# nrf54lm20a_enga_application register map
Vendor: Nordic Semiconductor; Series: nrf54l; File version: 1
CPU: CM33 r0p4, little endian, MPU, FPU, 3 interrupt priority bits, 270 interrupts, 4 SAU regions
Registers are 32-bit, read-write, reset 0x0 unless marked. A register's access mark holds for its fields unless they carry their own. Offsets are from the block's base; [hi:lo] are bit positions; lines under a group give offsets from that group; 'fields as' and 'values as' point back to an identical list.

## GLOBAL_NFCT_NS — NFC-A compatible radio NFC-A compatible radio 0
Base 0x400D6000
Same registers: GLOBAL_NFCT_S 0x500D6000
0x00 TASKS_ACTIVATE wo — Activate NFCT peripheral for incoming and outgoing frames, change state to activated
  [0] TASKS_ACTIVATE
    1=Trigger task
0x04 TASKS_DISABLE wo — Disable NFCT peripheral
  [0] TASKS_DISABLE
    1=Trigger task
0x08 TASKS_SENSE wo — Enable NFC sense field mode, change state to sense mode
  [0] TASKS_SENSE
    1=Trigger task
0x0C TASKS_STARTTX wo — Start transmission of an outgoing frame, change state to transmit
  [0] TASKS_STARTTX
    1=Trigger task
0x10 TASKS_STOPTX wo — Stops an issued transmission of a frame
  [0] TASKS_STOPTX
    1=Trigger task
0x1C TASKS_ENABLERXDATA wo — Initializes the EasyDMA for receive.
  [0] TASKS_ENABLERXDATA
    1=Trigger task
0x24 TASKS_GOIDLE wo — Force state machine to IDLE state
  [0] TASKS_GOIDLE
    1=Trigger task
0x28 TASKS_GOSLEEP wo — Force state machine to SLEEP_A state
  [0] TASKS_GOSLEEP
    1=Trigger task
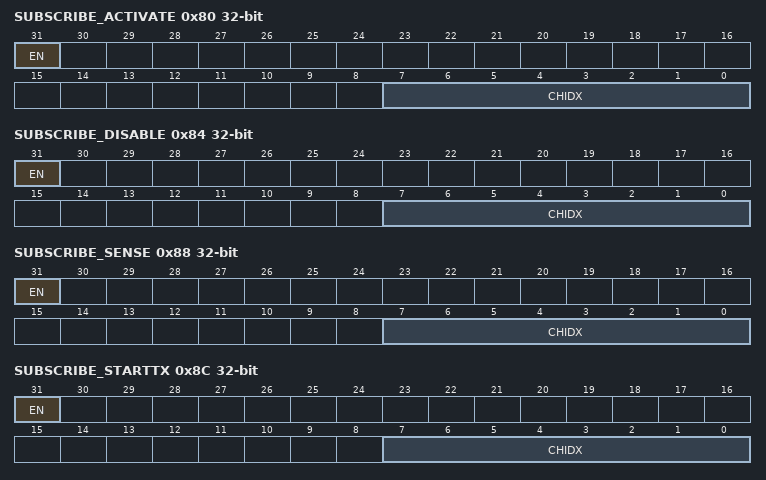
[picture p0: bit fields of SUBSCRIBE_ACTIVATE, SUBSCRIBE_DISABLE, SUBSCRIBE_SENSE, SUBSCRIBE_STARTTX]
0x80 SUBSCRIBE_ACTIVATE — Subscribe configuration for task ACTIVATE
  [31] EN
    0=Disabled (Disable subscription); 1=Enabled (Enable subscription)
  [7:0] CHIDX — DPPI channel that task ACTIVATE will subscribe to
0x84 SUBSCRIBE_DISABLE — Subscribe configuration for task DISABLE
  [31] EN
    values as SUBSCRIBE_ACTIVATE.EN
  [7:0] CHIDX — DPPI channel that task DISABLE will subscribe to
0x88 SUBSCRIBE_SENSE — Subscribe configuration for task SENSE
  [31] EN
    values as SUBSCRIBE_ACTIVATE.EN
  [7:0] CHIDX — DPPI channel that task SENSE will subscribe to
0x8C SUBSCRIBE_STARTTX — Subscribe configuration for task STARTTX
  [31] EN
    values as SUBSCRIBE_ACTIVATE.EN
  [7:0] CHIDX — DPPI channel that task STARTTX will subscribe to
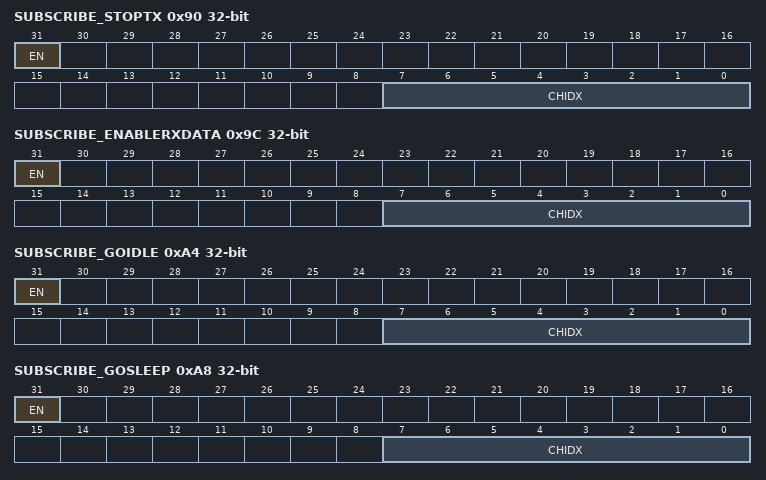
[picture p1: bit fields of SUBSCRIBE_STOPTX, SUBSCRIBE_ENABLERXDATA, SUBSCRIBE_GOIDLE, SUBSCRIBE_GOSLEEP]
0x90 SUBSCRIBE_STOPTX — Subscribe configuration for task STOPTX
  [31] EN
    values as SUBSCRIBE_ACTIVATE.EN
  [7:0] CHIDX — DPPI channel that task STOPTX will subscribe to
0x9C SUBSCRIBE_ENABLERXDATA — Subscribe configuration for task ENABLERXDATA
  [31] EN
    values as SUBSCRIBE_ACTIVATE.EN
  [7:0] CHIDX — DPPI channel that task ENABLERXDATA will subscribe to
0xA4 SUBSCRIBE_GOIDLE — Subscribe configuration for task GOIDLE
  [31] EN
    values as SUBSCRIBE_ACTIVATE.EN
  [7:0] CHIDX — DPPI channel that task GOIDLE will subscribe to
0xA8 SUBSCRIBE_GOSLEEP — Subscribe configuration for task GOSLEEP
  [31] EN
    values as SUBSCRIBE_ACTIVATE.EN
  [7:0] CHIDX — DPPI channel that task GOSLEEP will subscribe to
0x100 EVENTS_READY — The NFCT peripheral is ready to receive and send frames
  [0] EVENTS_READY
    0=NotGenerated (Event not generated); 1=Generated (Event generated)
0x104 EVENTS_FIELDDETECTED — Remote NFC field detected
  [0] EVENTS_FIELDDETECTED
    values as EVENTS_READY.EVENTS_READY
0x108 EVENTS_FIELDLOST — Remote NFC field lost
  [0] EVENTS_FIELDLOST
    values as EVENTS_READY.EVENTS_READY
0x10C EVENTS_TXFRAMESTART — Marks the start of the first symbol of a transmitted frame
  [0] EVENTS_TXFRAMESTART
    values as EVENTS_READY.EVENTS_READY
0x110 EVENTS_TXFRAMEEND — Marks the end of the last transmitted on-air symbol of a frame
  [0] EVENTS_TXFRAMEEND
    values as EVENTS_READY.EVENTS_READY
0x114 EVENTS_RXFRAMESTART — Marks the end of the first symbol of a received frame
  [0] EVENTS_RXFRAMESTART
    values as EVENTS_READY.EVENTS_READY
0x118 EVENTS_RXFRAMEEND — Received data has been checked (CRC, parity) and transferred to RAM, and EasyDMA has ended accessing the RX buffer
  [0] EVENTS_RXFRAMEEND
    values as EVENTS_READY.EVENTS_READY
0x11C EVENTS_ERROR — NFC error reported. The ERRORSTATUS register contains details on the source of the error.
  [0] EVENTS_ERROR
    values as EVENTS_READY.EVENTS_READY
0x128 EVENTS_RXERROR — NFC RX frame error reported. The FRAMESTATUS.RX register contains details on the source of the error.
  [0] EVENTS_RXERROR
    values as EVENTS_READY.EVENTS_READY
0x12C EVENTS_ENDRX — RX buffer (as defined by PACKETPTR and MAXLEN) in Data RAM full.
  [0] EVENTS_ENDRX
    values as EVENTS_READY.EVENTS_READY
0x130 EVENTS_ENDTX — Transmission of data in RAM has ended, and EasyDMA has ended accessing the TX buffer
  [0] EVENTS_ENDTX
    values as EVENTS_READY.EVENTS_READY
0x138 EVENTS_AUTOCOLRESSTARTED — Auto collision resolution process has started
  [0] EVENTS_AUTOCOLRESSTARTED
    values as EVENTS_READY.EVENTS_READY
0x148 EVENTS_COLLISION — NFC auto collision resolution error reported.
  [0] EVENTS_COLLISION
    values as EVENTS_READY.EVENTS_READY
0x14C EVENTS_SELECTED — NFC auto collision resolution successfully completed
  [0] EVENTS_SELECTED
    values as EVENTS_READY.EVENTS_READY
0x150 EVENTS_STARTED — EasyDMA is ready to receive or send frames.
  [0] EVENTS_STARTED
    values as EVENTS_READY.EVENTS_READY
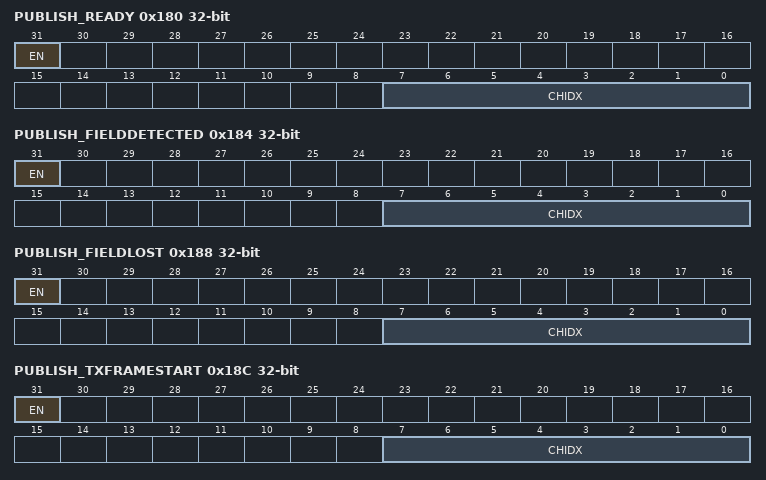
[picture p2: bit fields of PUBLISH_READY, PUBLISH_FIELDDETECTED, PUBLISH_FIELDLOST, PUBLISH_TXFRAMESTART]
0x180 PUBLISH_READY — Publish configuration for event READY
  [31] EN
    0=Disabled (Disable publishing); 1=Enabled (Enable publishing)
  [7:0] CHIDX — DPPI channel that event READY will publish to
0x184 PUBLISH_FIELDDETECTED — Publish configuration for event FIELDDETECTED
  [31] EN
    values as PUBLISH_READY.EN
  [7:0] CHIDX — DPPI channel that event FIELDDETECTED will publish to
0x188 PUBLISH_FIELDLOST — Publish configuration for event FIELDLOST
  [31] EN
    values as PUBLISH_READY.EN
  [7:0] CHIDX — DPPI channel that event FIELDLOST will publish to
0x18C PUBLISH_TXFRAMESTART — Publish configuration for event TXFRAMESTART
  [31] EN
    values as PUBLISH_READY.EN
  [7:0] CHIDX — DPPI channel that event TXFRAMESTART will publish to
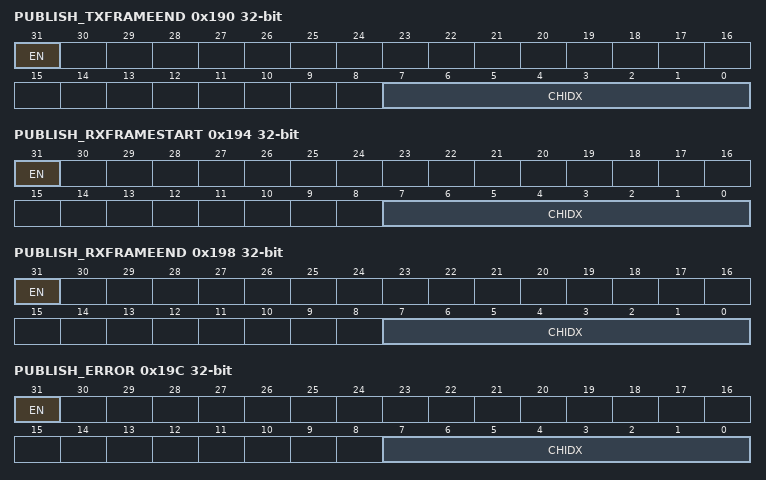
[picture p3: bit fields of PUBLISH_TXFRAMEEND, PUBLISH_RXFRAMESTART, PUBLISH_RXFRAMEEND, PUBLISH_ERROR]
0x190 PUBLISH_TXFRAMEEND — Publish configuration for event TXFRAMEEND
  [31] EN
    values as PUBLISH_READY.EN
  [7:0] CHIDX — DPPI channel that event TXFRAMEEND will publish to
0x194 PUBLISH_RXFRAMESTART — Publish configuration for event RXFRAMESTART
  [31] EN
    values as PUBLISH_READY.EN
  [7:0] CHIDX — DPPI channel that event RXFRAMESTART will publish to
0x198 PUBLISH_RXFRAMEEND — Publish configuration for event RXFRAMEEND
  [31] EN
    values as PUBLISH_READY.EN
  [7:0] CHIDX — DPPI channel that event RXFRAMEEND will publish to
0x19C PUBLISH_ERROR — Publish configuration for event ERROR
  [31] EN
    values as PUBLISH_READY.EN
  [7:0] CHIDX — DPPI channel that event ERROR will publish to
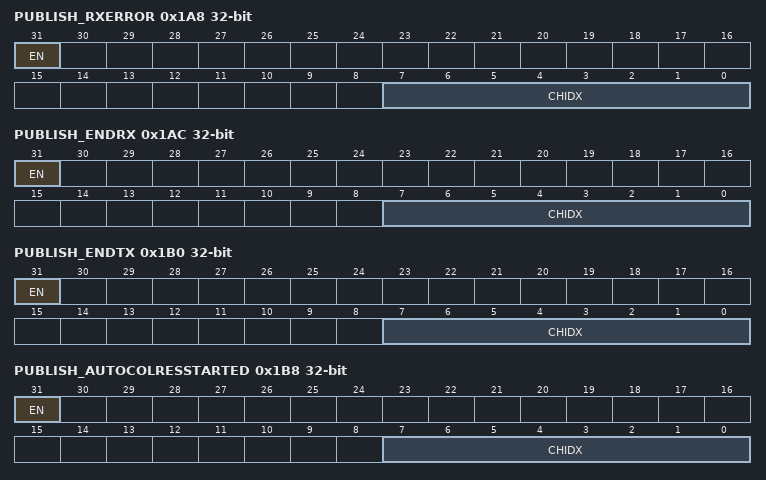
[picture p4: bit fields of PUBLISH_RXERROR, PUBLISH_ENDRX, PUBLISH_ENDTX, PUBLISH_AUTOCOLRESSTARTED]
0x1A8 PUBLISH_RXERROR — Publish configuration for event RXERROR
  [31] EN
    values as PUBLISH_READY.EN
  [7:0] CHIDX — DPPI channel that event RXERROR will publish to
0x1AC PUBLISH_ENDRX — Publish configuration for event ENDRX
  [31] EN
    values as PUBLISH_READY.EN
  [7:0] CHIDX — DPPI channel that event ENDRX will publish to
0x1B0 PUBLISH_ENDTX — Publish configuration for event ENDTX
  [31] EN
    values as PUBLISH_READY.EN
  [7:0] CHIDX — DPPI channel that event ENDTX will publish to
0x1B8 PUBLISH_AUTOCOLRESSTARTED — Publish configuration for event AUTOCOLRESSTARTED
  [31] EN
    values as PUBLISH_READY.EN
  [7:0] CHIDX — DPPI channel that event AUTOCOLRESSTARTED will publish to
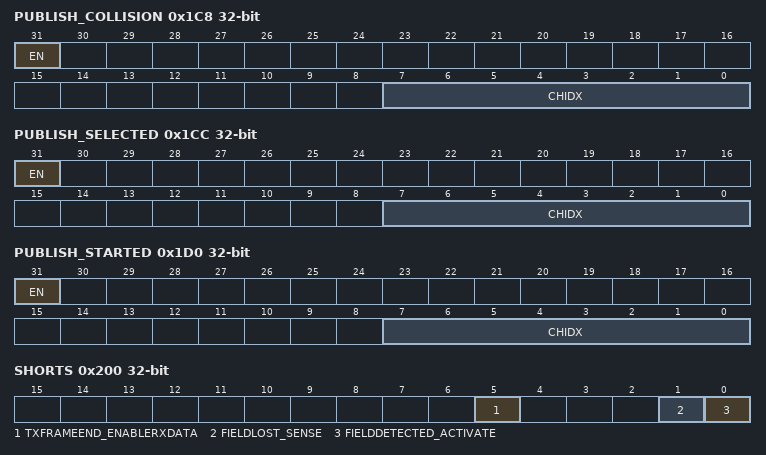
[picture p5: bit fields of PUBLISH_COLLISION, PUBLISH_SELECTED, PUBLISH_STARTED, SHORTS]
0x1C8 PUBLISH_COLLISION — Publish configuration for event COLLISION
  [31] EN
    values as PUBLISH_READY.EN
  [7:0] CHIDX — DPPI channel that event COLLISION will publish to
0x1CC PUBLISH_SELECTED — Publish configuration for event SELECTED
  [31] EN
    values as PUBLISH_READY.EN
  [7:0] CHIDX — DPPI channel that event SELECTED will publish to
0x1D0 PUBLISH_STARTED — Publish configuration for event STARTED
  [31] EN
    values as PUBLISH_READY.EN
  [7:0] CHIDX — DPPI channel that event STARTED will publish to
0x200 SHORTS — Shortcuts between local events and tasks
  [all] fields
    0=Disabled (Disable shortcut); 1=Enabled (Enable shortcut)
  [5] TXFRAMEEND_ENABLERXDATA — Shortcut between event TXFRAMEEND and task ENABLERXDATA
  [1] FIELDLOST_SENSE — Shortcut between event FIELDLOST and task SENSE
  [0] FIELDDETECTED_ACTIVATE — Shortcut between event FIELDDETECTED and task ACTIVATE
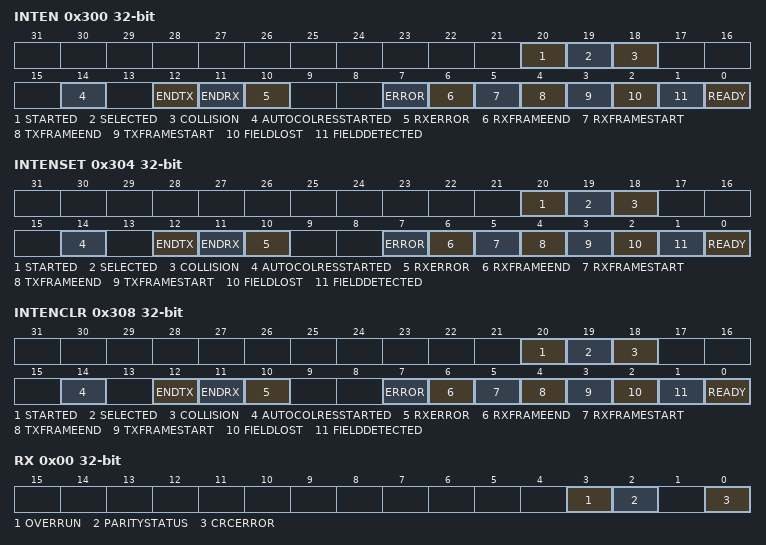
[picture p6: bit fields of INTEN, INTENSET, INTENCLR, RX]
0x300 INTEN — Enable or disable interrupt
  [all] fields
    0=Disabled; 1=Enabled
  [20] STARTED — Enable or disable interrupt for event STARTED
  [19] SELECTED — Enable or disable interrupt for event SELECTED
  [18] COLLISION — Enable or disable interrupt for event COLLISION
  [14] AUTOCOLRESSTARTED — Enable or disable interrupt for event AUTOCOLRESSTARTED
  [12] ENDTX — Enable or disable interrupt for event ENDTX
  [11] ENDRX — Enable or disable interrupt for event ENDRX
  [10] RXERROR — Enable or disable interrupt for event RXERROR
  [7] ERROR — Enable or disable interrupt for event ERROR
  [6] RXFRAMEEND — Enable or disable interrupt for event RXFRAMEEND
  [5] RXFRAMESTART — Enable or disable interrupt for event RXFRAMESTART
  [4] TXFRAMEEND — Enable or disable interrupt for event TXFRAMEEND
  [3] TXFRAMESTART — Enable or disable interrupt for event TXFRAMESTART
  [2] FIELDLOST — Enable or disable interrupt for event FIELDLOST
  [1] FIELDDETECTED — Enable or disable interrupt for event FIELDDETECTED
  [0] READY — Enable or disable interrupt for event READY
0x304 INTENSET — Enable interrupt
  [all] fields
    on read: 0=Disabled (Read: Disabled); 1=Enabled (Read: Enabled) | on write: 1=Set (Enable)
  [20] STARTED write-1-sets — Write '1' to enable interrupt for event STARTED
  [19] SELECTED write-1-sets — Write '1' to enable interrupt for event SELECTED
  [18] COLLISION write-1-sets — Write '1' to enable interrupt for event COLLISION
  [14] AUTOCOLRESSTARTED write-1-sets — Write '1' to enable interrupt for event AUTOCOLRESSTARTED
  [12] ENDTX write-1-sets — Write '1' to enable interrupt for event ENDTX
  [11] ENDRX write-1-sets — Write '1' to enable interrupt for event ENDRX
  [10] RXERROR write-1-sets — Write '1' to enable interrupt for event RXERROR
  [7] ERROR write-1-sets — Write '1' to enable interrupt for event ERROR
  [6] RXFRAMEEND write-1-sets — Write '1' to enable interrupt for event RXFRAMEEND
  [5] RXFRAMESTART write-1-sets — Write '1' to enable interrupt for event RXFRAMESTART
  [4] TXFRAMEEND write-1-sets — Write '1' to enable interrupt for event TXFRAMEEND
  [3] TXFRAMESTART write-1-sets — Write '1' to enable interrupt for event TXFRAMESTART
  [2] FIELDLOST write-1-sets — Write '1' to enable interrupt for event FIELDLOST
  [1] FIELDDETECTED write-1-sets — Write '1' to enable interrupt for event FIELDDETECTED
  [0] READY write-1-sets — Write '1' to enable interrupt for event READY
0x308 INTENCLR — Disable interrupt
  [all] fields
    on read: 0=Disabled (Read: Disabled); 1=Enabled (Read: Enabled) | on write: 1=Clear (Disable)
  [20] STARTED write-1-clears — Write '1' to disable interrupt for event STARTED
  [19] SELECTED write-1-clears — Write '1' to disable interrupt for event SELECTED
  [18] COLLISION write-1-clears — Write '1' to disable interrupt for event COLLISION
  [14] AUTOCOLRESSTARTED write-1-clears — Write '1' to disable interrupt for event AUTOCOLRESSTARTED
  [12] ENDTX write-1-clears — Write '1' to disable interrupt for event ENDTX
  [11] ENDRX write-1-clears — Write '1' to disable interrupt for event ENDRX
  [10] RXERROR write-1-clears — Write '1' to disable interrupt for event RXERROR
  [7] ERROR write-1-clears — Write '1' to disable interrupt for event ERROR
  [6] RXFRAMEEND write-1-clears — Write '1' to disable interrupt for event RXFRAMEEND
  [5] RXFRAMESTART write-1-clears — Write '1' to disable interrupt for event RXFRAMESTART
  [4] TXFRAMEEND write-1-clears — Write '1' to disable interrupt for event TXFRAMEEND
  [3] TXFRAMESTART write-1-clears — Write '1' to disable interrupt for event TXFRAMESTART
  [2] FIELDLOST write-1-clears — Write '1' to disable interrupt for event FIELDLOST
  [1] FIELDDETECTED write-1-clears — Write '1' to disable interrupt for event FIELDDETECTED
  [0] READY write-1-clears — Write '1' to disable interrupt for event READY
0x404 ERRORSTATUS write-1-clears — NFC Error Status register
  [0] FRAMEDELAYTIMEOUT — No STARTTX task triggered before expiration of the time set in FRAMEDELAYMAX
0x40C FRAMESTATUS group — Unspecified
  0x00 RX write-1-clears — Result of last incoming frame
    [3] OVERRUN — Overrun detected
      0=No overrun detected; 1=Overrun error
    [2] PARITYSTATUS — Parity status of received frame
      0=ParityOK (Frame received with parity OK); 1=ParityError (Frame received with parity error)
    [0] CRCERROR — No valid end of frame (EoF) detected
      0=CRCCorrect (Valid CRC detected); 1=CRCError (CRC received does not match local check)
0x410 NFCTAGSTATE ro — Current operating state of NFC tag
  [2:0] NFCTAGSTATE
    0=Disabled or sense; 2=RampUp; 3=Idle; 4=Receive; 5=FrameDelay; 6=Transmit
0x420 SLEEPSTATE ro — Sleep state during automatic collision resolution
  [0] SLEEPSTATE — Reflects the sleep state during automatic collision resolution. Set to IDLE by a GOIDLE task. Set to SLEEP_A when a valid SLEEP_REQ frame is received or by a GOSLEEP task.
    0=Idle (State is IDLE.); 1=SleepA (State is SLEEP_A.)
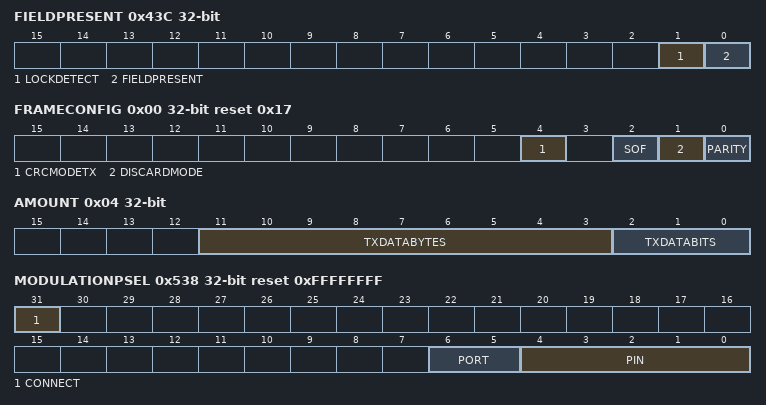
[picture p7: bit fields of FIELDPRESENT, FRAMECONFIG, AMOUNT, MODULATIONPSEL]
0x43C FIELDPRESENT ro — Indicates the presence or not of a valid field
  [1] LOCKDETECT — Indicates if the low level has locked to the field
    0=Not locked to field; 1=Locked to field
  [0] FIELDPRESENT — Indicates if a valid field is present. Available only in the activated state.
    0=NoField (No valid field detected); 1=FieldPresent (Valid field detected)
0x504 FRAMEDELAYMIN reset 0x480 — Minimum frame delay
  [15:0] FRAMEDELAYMIN — Minimum frame delay in number of 13.56 MHz clock cycles
0x508 FRAMEDELAYMAX reset 0x1000 — Maximum frame delay
  [19:0] FRAMEDELAYMAX — Maximum frame delay in number of 13.56 MHz clock cycles
0x50C FRAMEDELAYMODE reset 0x1 — Configuration register for the Frame Delay Timer
  [1:0] FRAMEDELAYMODE
    0=FreeRun (Transmission is independent of frame timer and will start when the STARTTX task is triggered. No timeout.); 1=Window (Frame is transmitted between FRAMEDELAYMIN and FRAMEDELAYMAX); 2=ExactVal (Frame is transmitted exactly at FRAMEDELAYMAX); 3=WindowGrid (Frame is transmitted on a bit grid between FRAMEDELAYMIN and FRAMEDELAYMAX)
0x510 PACKETPTR — Packet pointer for TXD and RXD data storage in Data RAM
  [31:0] PTR — Packet pointer for TXD and RXD data storage in Data RAM. This address is a byte-aligned RAM address.
0x514 MAXLEN — Size of the RAM buffer allocated to TXD and RXD data storage each
  [8:0] MAXLEN
0x518 TXD group — Unspecified
  0x00 FRAMECONFIG reset 0x17 — Configuration of outgoing frames
    [4] CRCMODETX — CRC mode for outgoing frames
      0=NoCRCTX (CRC is not added to the frame); 1=CRC16TX (16 bit CRC added to the frame based on all the data read from RAM that is used in the frame)
    [2] SOF — Adding SoF or not in TX frames
      0=NoSoF (SoF symbol not added); 1=SoF (SoF symbol added)
    [1] DISCARDMODE — Discarding unused bits at start or end of a frame
      0=DiscardEnd (Unused bits are discarded at end of frame (EoF)); 1=DiscardStart (Unused bits are discarded at start of frame (SoF))
    [0] PARITY — Indicates if parity is added to the frame
      0=NoParity (Parity is not added to TX frames); 1=Parity is added to TX frames
  0x04 AMOUNT — Size of outgoing frame
    [11:3] TXDATABYTES — Number of complete bytes that shall be included in the frame, excluding CRC, parity, and framing.
    [2:0] TXDATABITS — Number of bits in the last or first byte read from RAM that shall be included in the frame (excluding parity bit).
0x520 RXD group — Unspecified
  0x00 FRAMECONFIG reset 0x15 — Configuration of incoming frames
    [4] CRCMODERX — CRC mode for incoming frames
      0=NoCRCRX (CRC is not expected in RX frames); 1=CRC16RX (Last 16 bits in RX frame is CRC, CRC is checked and CRCSTATUS updated)
    [2] SOF — SoF expected or not in RX frames
      0=NoSoF (SoF symbol is not expected in RX frames); 1=SoF (SoF symbol is expected in RX frames)
    [0] PARITY — Indicates if parity expected in RX frame
      0=NoParity (Parity is not expected in RX frames); 1=Parity is expected in RX frames
  0x04 AMOUNT ro — Size of last incoming frame
    [11:3] RXDATABYTES — Number of complete bytes received in the frame (including CRC, but excluding parity and SoF/EoF framing)
    [2:0] RXDATABITS — Number of bits in the last byte in the frame, if less than 8 (including CRC, but excluding parity and SoF/EoF framing).
0x52C MODULATIONCTRL reset 0x1 — Enables the modulation output to a GPIO pin which can be connected to a second external antenna.
  [1:0] MODULATIONCTRL — Configuration of modulation control.
    0=Invalid, defaults to same behaviour as for Internal; 1=Internal (Use internal modulator only); 2=ModToGpio (Output digital modulation signal to a GPIO pin.); 3=InternalAndModToGpio (Use internal modulator and output digital modulation signal to a GPIO pin.)
0x538 MODULATIONPSEL reset 0xFFFFFFFF — Pin select for Modulation control
  [31] CONNECT — Connection
    1=Disconnected; 0=Connected
  [6:5] PORT — Port number
  [4:0] PIN — Pin number
0x550 MODE reset 0x1 — Configure EasyDMA mode
  [1:0] LPOP — Enable low-power operation, or use low-latency
    0=Low-latency operation; 1=Low-power operation; 3=Full Low-power operation
0x590 NFCID1 group — Unspecified
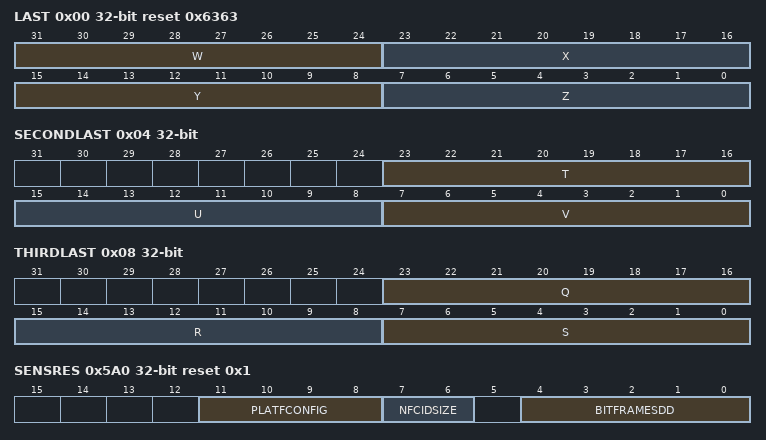
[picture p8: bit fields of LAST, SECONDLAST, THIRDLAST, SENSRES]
  0x00 LAST reset 0x6363 — Last NFCID1 part (4, 7 or 10 bytes ID)
    [31:24] W — NFCID1 byte W
    [23:16] X — NFCID1 byte X
    [15:8] Y — NFCID1 byte Y
    [7:0] Z — NFCID1 byte Z (very last byte sent)
  0x04 SECONDLAST — Second last NFCID1 part (7 or 10 bytes ID)
    [23:16] T — NFCID1 byte T
    [15:8] U — NFCID1 byte U
    [7:0] V — NFCID1 byte V
  0x08 THIRDLAST — Third last NFCID1 part (10 bytes ID)
    [23:16] Q — NFCID1 byte Q
    [15:8] R — NFCID1 byte R
    [7:0] S — NFCID1 byte S
0x59C AUTOCOLRESCONFIG reset 0x2 — Controls the auto collision resolution function. This setting must be done before the NFCT peripheral is activated.
  [0] MODE — Enables/disables auto collision resolution
    0=Enabled (Auto collision resolution enabled); 1=Disabled (Auto collision resolution disabled)
0x5A0 SENSRES reset 0x1 — NFC-A SENS_RES auto-response settings
  [11:8] PLATFCONFIG — Tag platform configuration as defined by the b4:b1 of byte 2 in SENS_RES response in the NFC Forum, NFC Digital Protocol Technical Specification
  [7:6] NFCIDSIZE — NFCID1 size. This value is used by the auto collision resolution engine.
    0=NFCID1Single (NFCID1 size: single (4 bytes)); 1=NFCID1Double (NFCID1 size: double (7 bytes)); 2=NFCID1Triple (NFCID1 size: triple (10 bytes))
  [4:0] BITFRAMESDD — Bit frame SDD as defined by the b5:b1 of byte 1 in SENS_RES response in the NFC Forum, NFC Digital Protocol Technical Specification
    0=SDD00000 (SDD pattern 00000); 1=SDD00001 (SDD pattern 00001); 2=SDD00010 (SDD pattern 00010); 4=SDD00100 (SDD pattern 00100); 8=SDD01000 (SDD pattern 01000); 16=SDD10000 (SDD pattern 10000)
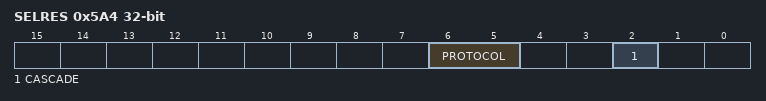
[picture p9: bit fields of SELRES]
0x5A4 SELRES — NFC-A SEL_RES auto-response settings
  [6:5] PROTOCOL — Protocol as defined by the b7:b6 of SEL_RES response in the NFC Forum, NFC Digital Protocol Technical Specification
  [2] CASCADE — Cascade as defined by the b3 of SEL_RES response in the NFC Forum, NFC Digital Protocol Technical Specification (controlled by hardware, shall be 0)
0x6D4 PADCONFIG reset 0x1 — NFC pad configuration
  [0] ENABLE — Enable NFC pads
    0=Disabled (NFC pads are used as GPIO pins); 1=Enabled (The NFC pads are configured as NFC antenna pins)
